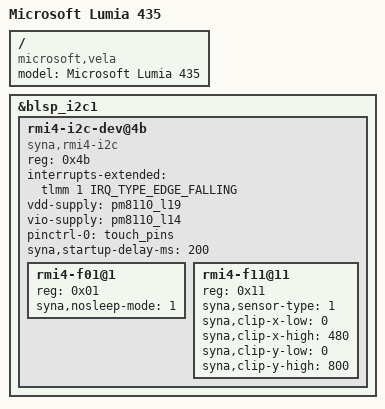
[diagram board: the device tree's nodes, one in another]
// SPDX-License-Identifier: BSD-3-Clause
/*
 * Copyright (c) 2021, Sebastiano Barezzi <barezzisebastiano@gmail.com>
 */

/dts-v1/;

#include "qcom-msm8210-msft-lumia-common.dtsi"

/ {
	model = "Microsoft Lumia 435";
	compatible = "microsoft,vela","qcom,msm8210";
};

&blsp_i2c1 {
	status = "okay";

	rmi4-i2c-dev@4b {
		compatible = "syna,rmi4-i2c";
		reg = <0x4b>;
		#address-cells = <1>;
		#size-cells = <0>;

		interrupts-extended = <&tlmm 1 IRQ_TYPE_EDGE_FALLING>;
		vdd-supply = <&pm8110_l19>;
		vio-supply = <&pm8110_l14>;

		pinctrl-names = "default";
		pinctrl-0 = <&touch_pins>;

		syna,startup-delay-ms = <200>;

		rmi4-f01@1 {
			reg = <0x01>;
			syna,nosleep-mode = <1>;
		};

		rmi4-f11@11 {
			reg = <0x11>;
			syna,sensor-type = <1>;
			syna,clip-x-low = <0>;
			syna,clip-x-high = <480>;
			syna,clip-y-low = <0>;
			syna,clip-y-high = <800>;
		};
	};
};
